VERSION ""

NS_ :

BS_:

BU_: BMS Third_Party_Device

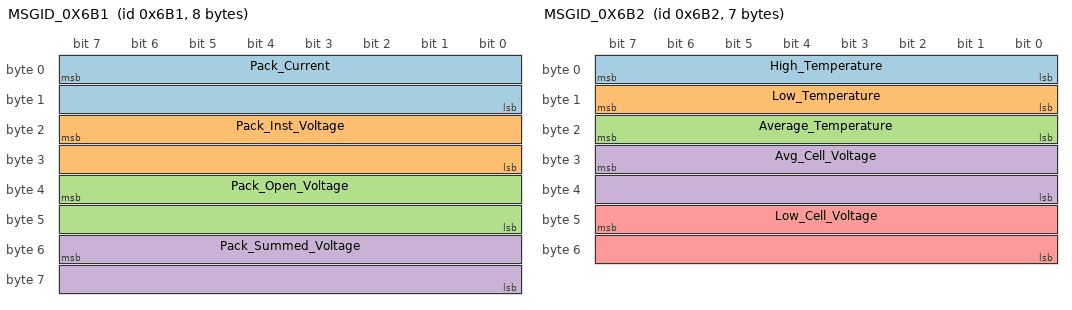
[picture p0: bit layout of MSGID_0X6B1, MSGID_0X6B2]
BO_ 1713 MSGID_0X6B1: 8 BMS
 SG_ Pack_Current : 7|16@0- (0.1,0) [0|0] "Amps"  Third_Party_Device
 SG_ Pack_Inst_Voltage : 23|16@0+ (0.1,0) [0|0] "Volts"  Third_Party_Device
 SG_ Pack_Open_Voltage : 39|16@0+ (0.1,0) [0|0] "Volts"  Third_Party_Device
 SG_ Pack_Summed_Voltage : 55|16@0+ (0.01,0) [0|0] "Volts"  Third_Party_Device

BO_ 1714 MSGID_0X6B2: 7 BMS
 SG_ High_Temperature : 7|8@0+ (1.0,0) [0|0] "Celsius"  Third_Party_Device
 SG_ Low_Temperature : 15|8@0+ (1.0,0) [0|0] "Celsius"  Third_Party_Device
 SG_ Average_Temperature : 23|8@0+ (1.0,0) [0|0] "Celsius"  Third_Party_Device
 SG_ Avg_Cell_Voltage : 31|16@0+ (1.0E-4,0) [0|0] "Volts"  Third_Party_Device
 SG_ Low_Cell_Voltage : 47|16@0+ (1.0E-4,0) [0|0] "Volts"  Third_Party_Device

BO_ 1715 MSGID_0X6B3: 1 BMS
 SG_ Pack_SOC : 7|8@0+ (0.5,0) [0|0] "Percent"  Third_Party_Device

BO_ 1716 MSGID_0X6B4: 1 BMS
 SG_ DTC_P0AA6_High_Voltage_Isolation_Fault : 0|1@1+ (1.0,0) [0|1] ""  Third_Party_Device

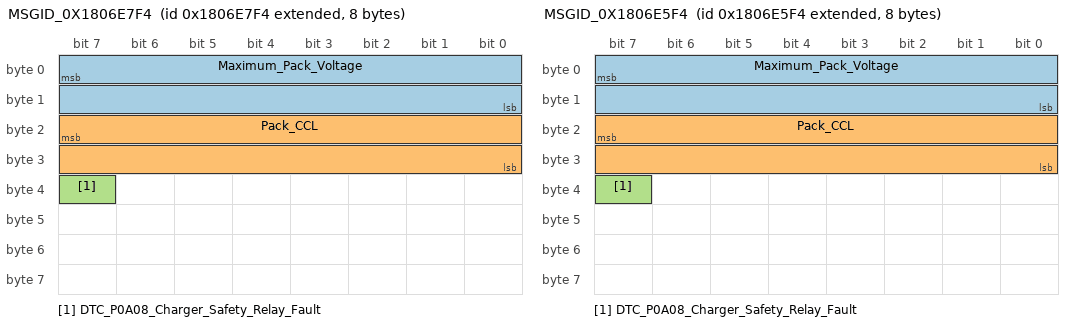
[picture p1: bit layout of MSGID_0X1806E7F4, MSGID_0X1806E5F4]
BO_ 2550589428 MSGID_0X1806E7F4: 8 BMS
 SG_ Maximum_Pack_Voltage : 7|16@0+ (0.1,0) [0|0] "Volts"  Third_Party_Device
 SG_ Pack_CCL : 23|16@0+ (0.1,0) [0|0] "Amps"  Third_Party_Device
 SG_ DTC_P0A08_Charger_Safety_Relay_Fault : 39|1@1+ (1.0,0) [0|1] ""  Third_Party_Device

BO_ 2550588916 MSGID_0X1806E5F4: 8 BMS
 SG_ Maximum_Pack_Voltage : 7|16@0+ (0.1,0) [0|0] "Volts"  Third_Party_Device
 SG_ Pack_CCL : 23|16@0+ (0.1,0) [0|0] "Amps"  Third_Party_Device
 SG_ DTC_P0A08_Charger_Safety_Relay_Fault : 39|1@1+ (1.0,0) [0|1] ""  Third_Party_Device

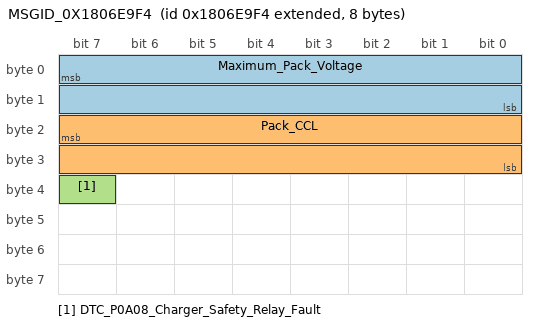
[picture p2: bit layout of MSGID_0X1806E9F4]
BO_ 2550589940 MSGID_0X1806E9F4: 8 BMS
 SG_ Maximum_Pack_Voltage : 7|16@0+ (0.1,0) [0|0] "Volts"  Third_Party_Device
 SG_ Pack_CCL : 23|16@0+ (0.1,0) [0|0] "Amps"  Third_Party_Device
 SG_ DTC_P0A08_Charger_Safety_Relay_Fault : 39|1@1+ (1.0,0) [0|1] ""  Third_Party_Device

CM_ BO_ 1713 "This ID Transmits at 8 ms.";
CM_ BO_ 1714 "This ID Transmits at 8 ms.";
CM_ BO_ 1715 "This ID Transmits at 104 ms.";
CM_ BO_ 1716 "This ID Transmits at 104 ms.";
CM_ BO_ 2550589428 "This ID Transmits at 808 ms.";
CM_ BO_ 2550588916 "This ID Transmits at 808 ms.";
CM_ BO_ 2550589940 "This ID Transmits at 808 ms.";
